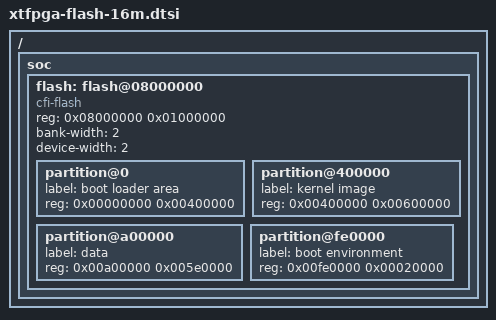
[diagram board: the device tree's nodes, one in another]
// SPDX-License-Identifier: GPL-2.0
/ {
	soc {
		flash: flash@08000000 {
			#address-cells = <1>;
			#size-cells = <1>;
			compatible = "cfi-flash";
			reg = <0x08000000 0x01000000>;
			bank-width = <2>;
			device-width = <2>;
			partition@0 {
				label = "boot loader area";
				reg = <0x00000000 0x00400000>;
			};
			partition@400000 {
				label = "kernel image";
				reg = <0x00400000 0x00600000>;
			};
			partition@a00000 {
				label = "data";
				reg = <0x00a00000 0x005e0000>;
			};
			partition@fe0000 {
				label = "boot environment";
				reg = <0x00fe0000 0x00020000>;
			};
		};
	};
};
